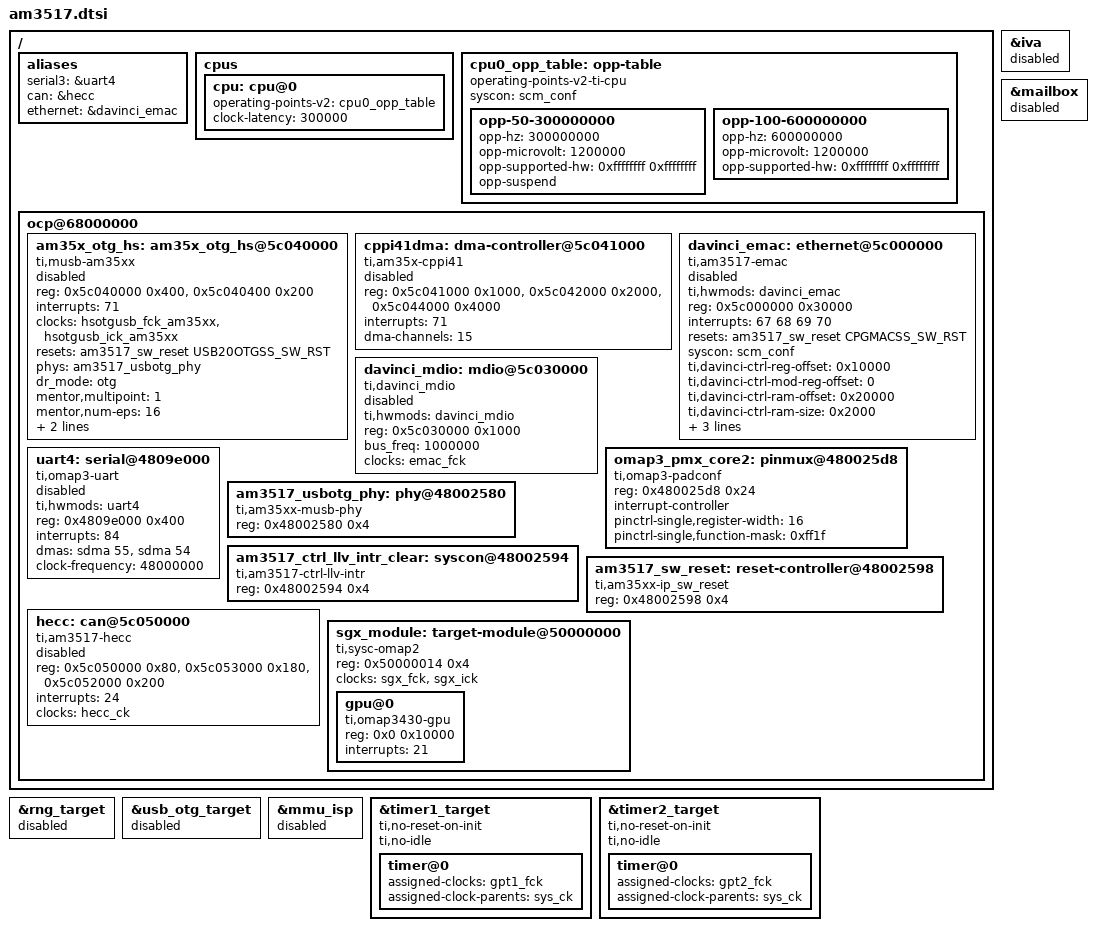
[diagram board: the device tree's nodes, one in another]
// SPDX-License-Identifier: GPL-2.0-only
/*
 * Device Tree Source for am3517 SoC
 *
 * Copyright (C) 2013 Texas Instruments Incorporated - https://www.ti.com/
 */

#include "omap3.dtsi"
#include <dt-bindings/reset/am3517-ip-sw-reset.h>

/* AM3517 doesn't appear to have the crypto engines defined in omap3.dtsi */
/delete-node/ &aes1_target;
/delete-node/ &aes2_target;

/ {
	aliases {
		serial3 = &uart4;
		can = &hecc;
		ethernet = &davinci_emac;
	};

	cpus {
		cpu: cpu@0 {
			/* Based on OMAP3630 variants OPP50 and OPP100 */
			operating-points-v2 = <&cpu0_opp_table>;

			clock-latency = <300000>; /* From legacy driver */
		};
	};

	cpu0_opp_table: opp-table {
		compatible = "operating-points-v2-ti-cpu";
		syscon = <&scm_conf>;
		/*
		 * AM3517 TRM only lists 600MHz @ 1.2V, but omap36xx
		 * appear to operate at 300MHz as well. Since AM3517 only
		 * lists one operating voltage, it will remain fixed at 1.2V
		 */
		opp-50-300000000 {
			/* OPP50 */
			opp-hz = /bits/ 64 <300000000>;
			opp-microvolt = <1200000>;
			opp-supported-hw = <0xffffffff 0xffffffff>;
			opp-suspend;
		};

		opp-100-600000000 {
			/* OPP100 */
			opp-hz = /bits/ 64 <600000000>;
			opp-microvolt = <1200000>;
			opp-supported-hw = <0xffffffff 0xffffffff>;
		};
	};

	ocp@68000000 {
		am35x_otg_hs: am35x_otg_hs@5c040000 {
			compatible = "ti,musb-am35xx";
			status = "disabled";
			reg = <0x5c040000 0x400>, <0x5c040400 0x200>;
			reg-names = "control", "mc";
			interrupts = <71>;
			interrupt-names = "mc";
			clocks = <&hsotgusb_fck_am35xx>, <&hsotgusb_ick_am35xx>;
			clock-names = "fck", "ick";
			resets = <&am3517_sw_reset USB20OTGSS_SW_RST>;
			phys = <&am3517_usbotg_phy>;
			dr_mode = "otg";
			mentor,multipoint = <1>;
			mentor,num-eps = <16>;
			mentor,ram-bits = <12>;
			syscon = <&am3517_ctrl_llv_intr_clear>;

#if 0
			dmas = <&cppi41dma  0 0>, <&cppi41dma  1 0>,
			       <&cppi41dma  2 0>, <&cppi41dma  3 0>,
			       <&cppi41dma  4 0>, <&cppi41dma  5 0>,
			       <&cppi41dma  6 0>, <&cppi41dma  7 0>,
			       <&cppi41dma  8 0>, <&cppi41dma  9 0>,
			       <&cppi41dma 10 0>, <&cppi41dma 11 0>,
			       <&cppi41dma 12 0>, <&cppi41dma 13 0>,
			       <&cppi41dma 14 0>, <&cppi41dma  0 1>,
			       <&cppi41dma  1 1>, <&cppi41dma  2 1>,
			       <&cppi41dma  3 1>, <&cppi41dma  4 1>,
			       <&cppi41dma  5 1>, <&cppi41dma  6 1>,
			       <&cppi41dma  7 1>, <&cppi41dma  8 1>,
			       <&cppi41dma  9 1>, <&cppi41dma 10 1>,
			       <&cppi41dma 11 1>, <&cppi41dma 12 1>,
			       <&cppi41dma 13 1>, <&cppi41dma 14 1>;

			dma-names = "rx1", "rx2", "rx3", "rx4", "rx5",
				    "rx6", "rx7", "rx8", "rx9", "rx10",
				    "rx11", "rx12", "rx13", "rx14", "rx15",
				    "tx1", "tx2", "tx3", "tx4", "tx5",
				    "tx6", "tx7", "tx8", "tx9", "tx10",
				    "tx11", "tx12", "tx13", "tx14", "tx15";
#endif
		};

		cppi41dma: dma-controller@5c041000 {
			compatible = "ti,am35x-cppi41";
			reg =  <0x5c041000 0x1000>,
			       <0x5c042000 0x2000>,
			       <0x5c044000 0x4000>;
			reg-names = "controller", "scheduler", "queuemgr";
			interrupts = <71>;
			#dma-cells = <2>;
			dma-channels = <15>;
			status = "disabled";
		};

		davinci_emac: ethernet@5c000000 {
			compatible = "ti,am3517-emac";
			ti,hwmods = "davinci_emac";
			status = "disabled";
			reg = <0x5c000000 0x30000>;
			interrupts = <67 68 69 70>;
			resets = <&am3517_sw_reset CPGMACSS_SW_RST>;
			syscon = <&scm_conf>;
			ti,davinci-ctrl-reg-offset = <0x10000>;
			ti,davinci-ctrl-mod-reg-offset = <0>;
			ti,davinci-ctrl-ram-offset = <0x20000>;
			ti,davinci-ctrl-ram-size = <0x2000>;
			ti,davinci-rmii-en = /bits/ 8 <1>;
			local-mac-address = [ 00 00 00 00 00 00 ];
			clocks = <&emac_ick>;
			clock-names = "ick";
		};

		davinci_mdio: mdio@5c030000 {
			compatible = "ti,davinci_mdio";
			ti,hwmods = "davinci_mdio";
			status = "disabled";
			reg = <0x5c030000 0x1000>;
			bus_freq = <1000000>;
			#address-cells = <1>;
			#size-cells = <0>;
			clocks = <&emac_fck>;
			clock-names = "fck";
		};

		uart4: serial@4809e000 {
			compatible = "ti,omap3-uart";
			ti,hwmods = "uart4";
			status = "disabled";
			reg = <0x4809e000 0x400>;
			interrupts = <84>;
			dmas = <&sdma 55 &sdma 54>;
			dma-names = "tx", "rx";
			clock-frequency = <48000000>;
		};

		omap3_pmx_core2: pinmux@480025d8 {
			compatible = "ti,omap3-padconf", "pinctrl-single";
			reg = <0x480025d8 0x24>;
			#address-cells = <1>;
			#size-cells = <0>;
			#pinctrl-cells = <1>;
			#interrupt-cells = <1>;
			interrupt-controller;
			pinctrl-single,register-width = <16>;
			pinctrl-single,function-mask = <0xff1f>;
		};

		am3517_usbotg_phy: phy@48002580 {
			compatible = "ti,am35xx-musb-phy";
			reg = <0x48002580 0x4>;
			#phy-cells = <0>;
		};

		am3517_ctrl_llv_intr_clear: syscon@48002594 {
		        compatible = "ti,am3517-ctrl-llv-intr", "syscon";
		        reg = <0x48002594 0x4>;
		};


		am3517_sw_reset: reset-controller@48002598 {
			compatible = "ti,am35xx-ip_sw_reset";
			reg = <0x48002598 0x4>;
			#reset-cells = <1>;
		};

		hecc: can@5c050000 {
			compatible = "ti,am3517-hecc";
			status = "disabled";
			reg = <0x5c050000 0x80>,
			      <0x5c053000 0x180>,
			      <0x5c052000 0x200>;
			reg-names = "hecc", "hecc-ram", "mbx";
			interrupts = <24>;
			clocks = <&hecc_ck>;
		};

		/*
		 * On am3517 the OCP registers do not seem to be accessible
		 * similar to the omap34xx. Maybe SGX is permanently set to
		 * "OCP bypass mode", or maybe there is OCP_SYSCONFIG that is
		 * write-only at 0x50000e10. We detect SGX based on the SGX
		 * revision register instead of the unreadable OCP revision
		 * register.
		 */
		sgx_module: target-module@50000000 {
			compatible = "ti,sysc-omap2", "ti,sysc";
			reg = <0x50000014 0x4>;
			reg-names = "rev";
			clocks = <&sgx_fck>, <&sgx_ick>;
			clock-names = "fck", "ick";
			#address-cells = <1>;
			#size-cells = <1>;
			ranges = <0 0x50000000 0x10000>;

			gpu@0 {
				compatible = "ti,omap3430-gpu", "img,powervr-sgx530";
				reg = <0x0 0x10000>; /* 64kB */
				interrupts = <21>;
			};
		};
	};
};

/* Not currently working, probably needs at least different clocks */
&rng_target {
	status = "disabled";
	/delete-property/ clocks;
};

/* Table Table 5-79 of the TRM shows 480ab000 is reserved */
&usb_otg_target {
	status = "disabled";
};

&iva {
	status = "disabled";
};

&mailbox {
	status = "disabled";
};

&mmu_isp {
	status = "disabled";
};

#include "am35xx-clocks.dtsi"
#include "omap36xx-am35xx-omap3430es2plus-clocks.dtsi"

/* Preferred always-on timer for clocksource */
&timer1_target {
	ti,no-reset-on-init;
	ti,no-idle;
	timer@0 {
		assigned-clocks = <&gpt1_fck>;
		assigned-clock-parents = <&sys_ck>;
	};
};

/* Preferred timer for clockevent */
&timer2_target {
	ti,no-reset-on-init;
	ti,no-idle;
	timer@0 {
		assigned-clocks = <&gpt2_fck>;
		assigned-clock-parents = <&sys_ck>;
	};
};
